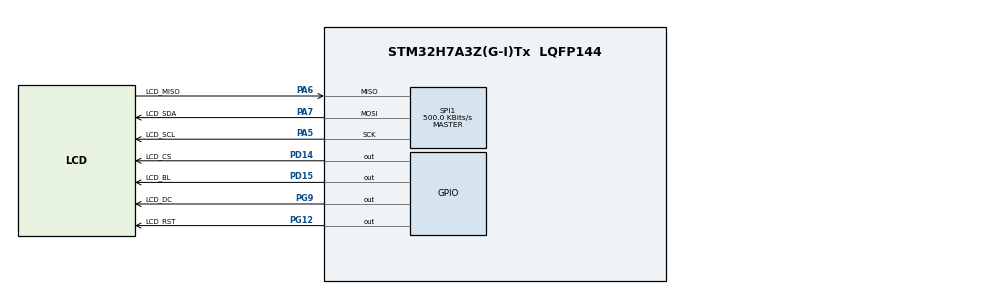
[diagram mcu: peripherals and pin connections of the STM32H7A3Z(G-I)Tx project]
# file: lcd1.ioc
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Mcu.Family=STM32H7
Mcu.Name=STM32H7A3Z(G-I)Tx
Mcu.Package=LQFP144
NVIC.PriorityGroup=NVIC_PRIORITYGROUP_4
PA5.GPIO_Label=LCD_SCL
PA5.GPIO_Speed=GPIO_SPEED_FREQ_HIGH
PA5.Mode=Full_Duplex_Master
PA5.Signal=SPI1_SCK
PA6.GPIO_Label=LCD_MISO
PA6.GPIO_Speed=GPIO_SPEED_FREQ_HIGH
PA6.Mode=Full_Duplex_Master
PA6.Signal=SPI1_MISO
PA7.GPIO_Label=LCD_SDA
PA7.GPIO_Speed=GPIO_SPEED_FREQ_HIGH
PA7.Mode=Full_Duplex_Master
PA7.Signal=SPI1_MOSI
PD14.GPIO_Label=LCD_CS
PD14.GPIO_ModeDefaultOutputPP=GPIO_MODE_OUTPUT_PP
PD14.GPIO_Speed=GPIO_SPEED_FREQ_HIGH
PD14.Signal=GPIO_Output
PD15.GPIO_Label=LCD_BL
PD15.GPIO_ModeDefaultOutputPP=GPIO_MODE_OUTPUT_PP
PD15.GPIO_Speed=GPIO_SPEED_FREQ_HIGH
PD15.Signal=GPIO_Output
PG12.GPIO_Label=LCD_RST
PG12.GPIO_ModeDefaultOutputPP=GPIO_MODE_OUTPUT_PP
PG12.GPIO_PuPd=GPIO_NOPULL
PG12.GPIO_Speed=GPIO_SPEED_FREQ_HIGH
PG12.Signal=GPIO_Output
PG9.GPIO_Label=LCD_DC
PG9.GPIO_ModeDefaultOutputPP=GPIO_MODE_OUTPUT_PP
PG9.GPIO_Speed=GPIO_SPEED_FREQ_HIGH
PG9.Signal=GPIO_Output
ProjectManager.HeapSize=0x200
ProjectManager.StackSize=0x400
ProjectManager.TargetToolchain=STM32CubeIDE
RCC.ADCFreq_Value=129000000
RCC.APB1Freq_Value=32000000
RCC.APB2Freq_Value=32000000
RCC.APB3Freq_Value=32000000
RCC.APB4Freq_Value=32000000
RCC.CDPPRE=RCC_APB3_DIV2
RCC.CDPPRE1=RCC_APB1_DIV2
RCC.CDPPRE2=RCC_APB2_DIV2
RCC.CortexFreq_Value=64000000
RCC.DIVM1=4
RCC.DIVN1=8
RCC.DIVQ1=1
RCC.HCLKFreq_Value=64000000
RCC.PLLFRACN=0
RCC.SRDPPRE=RCC_APB4_DIV2
RCC.SYSCLKFreq_VALUE=64000000
RCC.USBFreq_Value=128000000
SPI1.BaudRatePrescaler=SPI_BAUDRATEPRESCALER_256
SPI1.CalculateBaudRate=500.0 KBits/s
SPI1.DataSize=SPI_DATASIZE_8BIT
SPI1.Direction=SPI_DIRECTION_2LINES
SPI1.Mode=SPI_MODE_MASTER
SPI1.VirtualType=VM_MASTER
board=custom

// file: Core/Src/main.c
/* USER CODE BEGIN Header */
/**
  ******************************************************************************
  * @file           : main.c
  * @brief          : Main program body
  ******************************************************************************
  * @attention
  *
  * Copyright (c) 2023 STMicroelectronics.
  * All rights reserved.
  *
  * This software is licensed under terms that can be found in the LICENSE file
  * in the root directory of this software component.
  * If no LICENSE file comes with this software, it is provided AS-IS.
  *
  ******************************************************************************
  */
/* USER CODE END Header */
#include "main.h"

SPI_HandleTypeDef hspi1;

void SystemClock_Config(void);
static void MX_GPIO_Init(void);
static void MX_SPI1_Init(void);

int main(void)
{

  /* MCU Configuration--------------------------------------------------------*/

  /* Reset of all peripherals, Initializes the Flash interface and the Systick. */
  HAL_Init();

  /* USER CODE BEGIN Init */
  LCD_Init();
  /* USER CODE END Init */

  /* Configure the system clock */
  SystemClock_Config();

  /* Initialize all configured peripherals */
  MX_GPIO_Init();
  MX_SPI1_Init();
  /* USER CODE BEGIN 2 */
  LCD_Fill(0,0,LCD_W,LCD_H,WHITE);
  float t=0;
  /* USER CODE END 2 */

  /* Infinite loop */
  while (1)
  {

    /* USER CODE BEGIN 3 */
    LCD_ShowString(24,30,"LCD_W:",RED,WHITE,16,0);
		LCD_ShowIntNum(72,30,LCD_W,3,RED,WHITE,16);
		LCD_ShowString(24,50,"LCD_H:",RED,WHITE,16,0);
		LCD_ShowIntNum(72,50,LCD_H,3,RED,WHITE,16);
		LCD_ShowFloatNum1(20,80,t,4,RED,WHITE,16);
    t+=0.11;
    LCD_ShowPicture(65,80,40,40,gImage_1);
  }
  /* USER CODE END 3 */
}

void SystemClock_Config(void)
{
  RCC_OscInitTypeDef RCC_OscInitStruct = {0};
  RCC_ClkInitTypeDef RCC_ClkInitStruct = {0};

  /*AXI clock gating */
  RCC->CKGAENR = 0xFFFFFFFF;

  /** Supply configuration update enable
  */
  HAL_PWREx_ConfigSupply(PWR_LDO_SUPPLY);

  /** Configure the main internal regulator output voltage
  */
  __HAL_PWR_VOLTAGESCALING_CONFIG(PWR_REGULATOR_VOLTAGE_SCALE3);

  while(!__HAL_PWR_GET_FLAG(PWR_FLAG_VOSRDY)) {}

  /** Initializes the RCC Oscillators according to the specified parameters
  * in the RCC_OscInitTypeDef structure.
  */
  RCC_OscInitStruct.OscillatorType = RCC_OSCILLATORTYPE_HSI;
  RCC_OscInitStruct.HSIState = RCC_HSI_DIV1;
  RCC_OscInitStruct.HSICalibrationValue = RCC_HSICALIBRATION_DEFAULT;
  RCC_OscInitStruct.PLL.PLLState = RCC_PLL_ON;
  RCC_OscInitStruct.PLL.PLLSource = RCC_PLLSOURCE_HSI;
  RCC_OscInitStruct.PLL.PLLM = 4;
  RCC_OscInitStruct.PLL.PLLN = 8;
  RCC_OscInitStruct.PLL.PLLP = 2;
  RCC_OscInitStruct.PLL.PLLQ = 1;
  RCC_OscInitStruct.PLL.PLLR = 2;
  RCC_OscInitStruct.PLL.PLLRGE = RCC_PLL1VCIRANGE_3;
  RCC_OscInitStruct.PLL.PLLVCOSEL = RCC_PLL1VCOWIDE;
  RCC_OscInitStruct.PLL.PLLFRACN = 0;
  if (HAL_RCC_OscConfig(&RCC_OscInitStruct) != HAL_OK)
  {
    Error_Handler();
  }

  /** Initializes the CPU, AHB and APB buses clocks
  */
  RCC_ClkInitStruct.ClockType = RCC_CLOCKTYPE_HCLK|RCC_CLOCKTYPE_SYSCLK
                              |RCC_CLOCKTYPE_PCLK1|RCC_CLOCKTYPE_PCLK2
                              |RCC_CLOCKTYPE_D3PCLK1|RCC_CLOCKTYPE_D1PCLK1;
  RCC_ClkInitStruct.SYSCLKSource = RCC_SYSCLKSOURCE_HSI;
  RCC_ClkInitStruct.SYSCLKDivider = RCC_SYSCLK_DIV1;
  RCC_ClkInitStruct.AHBCLKDivider = RCC_HCLK_DIV1;
  RCC_ClkInitStruct.APB3CLKDivider = RCC_APB3_DIV2;
  RCC_ClkInitStruct.APB1CLKDivider = RCC_APB1_DIV2;
  RCC_ClkInitStruct.APB2CLKDivider = RCC_APB2_DIV2;
  RCC_ClkInitStruct.APB4CLKDivider = RCC_APB4_DIV2;

  if (HAL_RCC_ClockConfig(&RCC_ClkInitStruct, FLASH_LATENCY_2) != HAL_OK)
  {
    Error_Handler();
  }
}

static void MX_SPI1_Init(void)
{

  /* SPI1 parameter configuration*/
  hspi1.Instance = SPI1;
  hspi1.Init.Mode = SPI_MODE_MASTER;
  hspi1.Init.Direction = SPI_DIRECTION_2LINES;
  hspi1.Init.DataSize = SPI_DATASIZE_8BIT;
  hspi1.Init.CLKPolarity = SPI_POLARITY_LOW;
  hspi1.Init.CLKPhase = SPI_PHASE_1EDGE;
  hspi1.Init.NSS = SPI_NSS_SOFT;
  hspi1.Init.BaudRatePrescaler = SPI_BAUDRATEPRESCALER_256;
  hspi1.Init.FirstBit = SPI_FIRSTBIT_MSB;
  hspi1.Init.TIMode = SPI_TIMODE_DISABLE;
  hspi1.Init.CRCCalculation = SPI_CRCCALCULATION_DISABLE;
  hspi1.Init.CRCPolynomial = 0x0;
  hspi1.Init.NSSPMode = SPI_NSS_PULSE_ENABLE;
  hspi1.Init.NSSPolarity = SPI_NSS_POLARITY_LOW;
  hspi1.Init.FifoThreshold = SPI_FIFO_THRESHOLD_01DATA;
  hspi1.Init.TxCRCInitializationPattern = SPI_CRC_INITIALIZATION_ALL_ZERO_PATTERN;
  hspi1.Init.RxCRCInitializationPattern = SPI_CRC_INITIALIZATION_ALL_ZERO_PATTERN;
  hspi1.Init.MasterSSIdleness = SPI_MASTER_SS_IDLENESS_00CYCLE;
  hspi1.Init.MasterInterDataIdleness = SPI_MASTER_INTERDATA_IDLENESS_00CYCLE;
  hspi1.Init.MasterReceiverAutoSusp = SPI_MASTER_RX_AUTOSUSP_DISABLE;
  hspi1.Init.MasterKeepIOState = SPI_MASTER_KEEP_IO_STATE_DISABLE;
  hspi1.Init.IOSwap = SPI_IO_SWAP_DISABLE;
  if (HAL_SPI_Init(&hspi1) != HAL_OK)
  {
    Error_Handler();
  }

}

static void MX_GPIO_Init(void)
{
  GPIO_InitTypeDef GPIO_InitStruct = {0};

  /* GPIO Ports Clock Enable */
  __HAL_RCC_GPIOA_CLK_ENABLE();
  __HAL_RCC_GPIOD_CLK_ENABLE();
  __HAL_RCC_GPIOG_CLK_ENABLE();

  /*Configure GPIO pin Output Level */
  HAL_GPIO_WritePin(GPIOD, LCD_CS_Pin|LCD_BL_Pin, GPIO_PIN_RESET);

  /*Configure GPIO pin Output Level */
  HAL_GPIO_WritePin(GPIOG, LCD_DC_Pin|LCD_RST_Pin, GPIO_PIN_RESET);

  /*Configure GPIO pins : LCD_CS_Pin LCD_BL_Pin */
  GPIO_InitStruct.Pin = LCD_CS_Pin|LCD_BL_Pin;
  GPIO_InitStruct.Mode = GPIO_MODE_OUTPUT_PP;
  GPIO_InitStruct.Pull = GPIO_NOPULL;
  GPIO_InitStruct.Speed = GPIO_SPEED_FREQ_HIGH;
  HAL_GPIO_Init(GPIOD, &GPIO_InitStruct);

  /*Configure GPIO pins : LCD_DC_Pin LCD_RST_Pin */
  GPIO_InitStruct.Pin = LCD_DC_Pin|LCD_RST_Pin;
  GPIO_InitStruct.Mode = GPIO_MODE_OUTPUT_PP;
  GPIO_InitStruct.Pull = GPIO_NOPULL;
  GPIO_InitStruct.Speed = GPIO_SPEED_FREQ_HIGH;
  HAL_GPIO_Init(GPIOG, &GPIO_InitStruct);

}

void Error_Handler(void)
{
  __disable_irq();
  while (1)
  {
  }
}
